# RL6845_IP_SVD register map
Vendor: Realtek
Registers are 32-bit, read-write, reset 0x0 unless marked. A register's access mark holds for its fields unless they carry their own. Offsets are from the block's base; [hi:lo] are bit positions; {n}, {i} and the like mark numbered series.

## PAGE0
Base 0x40000000
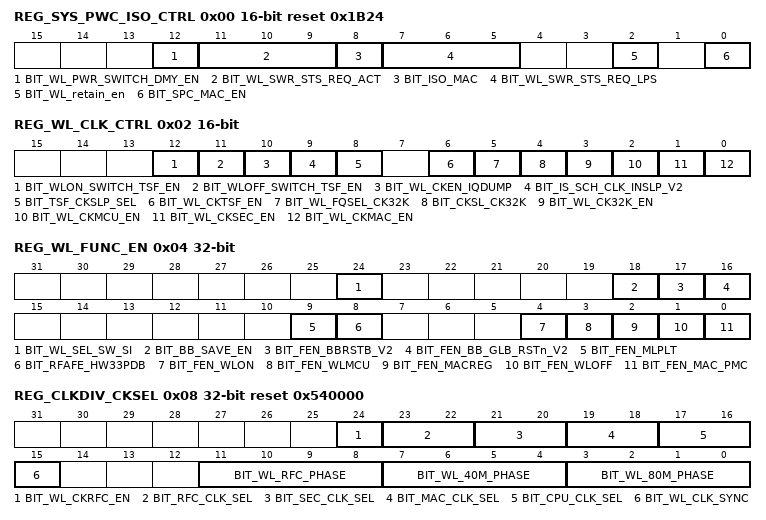
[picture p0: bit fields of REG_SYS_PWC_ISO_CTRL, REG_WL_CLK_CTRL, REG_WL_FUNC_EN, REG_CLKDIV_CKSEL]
0x00 REG_SYS_PWC_ISO_CTRL 16-bit reset 0x1B24
  [12] BIT_WL_PWR_SWITCH_DMY_EN — 1:enable wl_dummy_en when wlan is switching power mode 0:disable wl_dummy_en when wlan is switching power mode
  [11:9] BIT_WL_SWR_STS_REQ_ACT — 000: RSVD 001: state1 0.7/PC/PFM 010: state2 0.8/PC/PFM 011: state3 0.9/PC/PFM 100: state4 0.9/SLP/PFM 101: state5 0.9/SLP/PWM 110: state6 0.9/NORM/PWM 111: state7 1.0/NORM/PWM
  [8] BIT_ISO_MAC — Isolation control for MAC, 1: isolation; 0: attach
  [7:5] BIT_WL_SWR_STS_REQ_LPS — 000: RSVD 001: state1 0.7/PC/PFM 010: state2 0.8/PC/PFM 011: state3 0.9/PC/PFM 100: state4 0.9/SLP/PFM 101: state5 0.9/SLP/PWM 110: state6 0.9/NORM/PWM 111: state7 1.0/NORM/PWM
  [2] BIT_WL_retain_en — 1 to 0:gen req to restore register in power on flow 1:gen req to backup register in power on flow
  [0] BIT_SPC_MAC_EN — 1: Enable WLOFF power cut
0x02 REG_WL_CLK_CTRL 16-bit access per field
  [12] BIT_WLON_SWITCH_TSF_EN rw — enable wlpmc switch TSF clock to MAC clock
  [11] BIT_WLOFF_SWITCH_TSF_EN rw — enable wlpmc switch TSF clock to 32K clock
  [10] BIT_WL_CKEN_IQDUMP rw — 0: disable clock for iqdump (LA MODE) 1: enable clock for iqdump (LA MODE) same clock source as security clock
  [9] BIT_IS_SCH_CLK_INSLP_V2 ro — WL TSF clock status: 0: MAC clock 1: 32K clock
  [8] BIT_TSF_CKSLP_SEL rw — 1: TSF clock switch to 32.768KHz; 0: TSF clock switch to MAC clock
  [6] BIT_WL_CKTSF_EN rw — 1: enable tsf clock; 0: gated
  [5] BIT_WL_FQSEL_CK32K rw — 1:32K frequency select 32.768KHz 0:32K frequency select 32KHz
  [4] BIT_CKSL_CK32K rw — 1:select MAC internal 32K clk, 0:select MAC external 32K clk
  [3] BIT_WL_CK32K_EN rw — 1: enable 32k clock; 0: gated
  [2] BIT_WL_CKMCU_EN rw — 1: enable MCU engine clock; 0: gated
  [1] BIT_WL_CKSEC_EN rw — 1: enable MAC security engine clock; 0: gated
  [0] BIT_WL_CKMAC_EN rw — 1: enable MAC clock; 0: gated
0x04 REG_WL_FUNC_EN access per field
  [24] BIT_WL_SEL_SW_SI rw — indicate SW use indirect path to access WLRFC register
  [18] BIT_BB_SAVE_EN rw — 1 to 0:gen req to restore register in power on flow 1:gen req to backup register in power on flow
  [17] BIT_FEN_BBRSTB_V2 rw — When this bit is set to "0", CCK and OFDM are disabled, and clock are gated. Otherwise, CCK and OFDM are enabled.
  [16] BIT_FEN_BB_GLB_RSTn_V2 rw — When this bit is set to "0", whole BB is reset. When this bit is set, BB is enabled.
  [9] BIT_FEN_MLPLT rw
  [8] BIT_RFAFE_HW33PDB rw
  [4] BIT_FEN_WLON rw — 1: enable WL partial ON; 0: reset
  [3] BIT_FEN_WLMCU rw — 1: enable WLMCU; 0: reset
  [2] BIT_FEN_MACREG rw — 1: enable MAC REG; 0: reset
  [1] BIT_FEN_WLOFF rw — 1: enable WLOFF; 0: reset
  [0] BIT_FEN_MAC_PMC rw — 1: enable MAC PMC; 0: reset
0x08 REG_CLKDIV_CKSEL reset 0x540000
  [24] BIT_WL_CKRFC_EN — 1: enable WLRFC clock; 0: gated
  [23:22] BIT_RFC_CLK_SEL — 11/10:40M 01:80M 00:160M
  [21:20] BIT_SEC_CLK_SEL — 11/10:40M 01:80M 00:160M
  [19:18] BIT_MAC_CLK_SEL — 11/10:20M 01:40M 00:80M
  [17:16] BIT_CPU_CLK_SEL
  [15] BIT_WL_CLK_SYNC — 1: sync 40M/80M clock phase with PLL
  [11:8] BIT_WL_RFC_PHASE — 80M WLRFC clock phase control
  [7:4] BIT_WL_40M_PHASE — 40M MAC clock phase control
  [3:0] BIT_WL_80M_PHASE — 80M security clock phase control
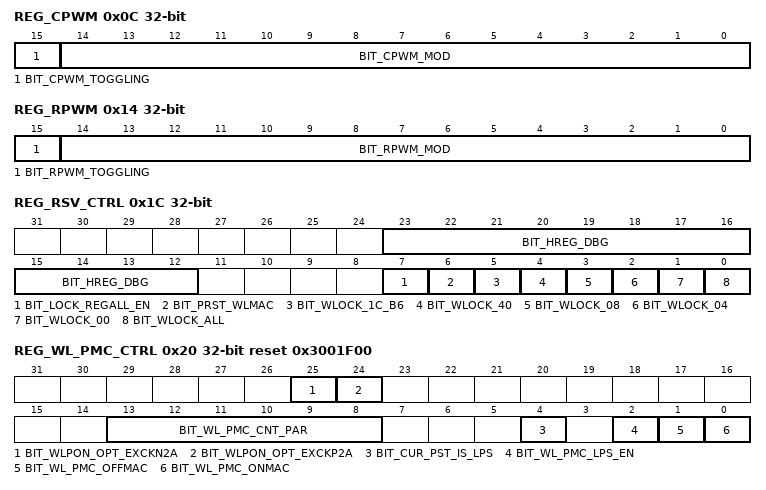
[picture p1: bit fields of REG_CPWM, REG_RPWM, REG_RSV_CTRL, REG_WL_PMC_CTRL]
0x0C REG_CPWM
  [15] BIT_CPWM_TOGGLING — Toggling bit : one bit sequence number bit. When this bit is toggled, interrupt is send to HISR.CPWMINT.
  [14:0] BIT_CPWM_MOD — The current power mode index.
0x14 REG_RPWM — register for hrpwm
  [15] BIT_RPWM_TOGGLING — Toggling bit : one bit sequence number bit. When this bit is toggled, interrupt is send to FISR.RPWMINT.
  [14:0] BIT_RPWM_MOD — The current power mode index.
0x1C REG_RSV_CTRL access per field
  [23:12] BIT_HREG_DBG ro — HREG Access Debug information
  [7] BIT_LOCK_REGALL_EN rw — 1:Enable 'Locked All' setting by Hardware, 0: Hardware Enable 'Locked All' denied.
  [6] BIT_PRST_WLMAC rw
  [5] BIT_WLOCK_1C_B6 rw — 1:Register Write Locked, 0: Register Accessible by SW/FW (offset:0x001C[6])
  [4] BIT_WLOCK_40 rw — 1:Register Write Locked, 0: Register Accessible by SW/FW (offset:0x0040h~0x0043h)
  [3] BIT_WLOCK_08 rw — 1:Register Write Locked, 0: Register Accessible by SW/FW (offset:0x0008h~0x000Bh)
  [2] BIT_WLOCK_04 rw — 1:Register Write Locked, 0: Register Accessible by SW/FW (offset:0x0004h~0x0007h)
  [1] BIT_WLOCK_00 rw — 1:Register Write Locked, 0: Register Accessible by SW/FW (offset:0x0000h~0x0003h)
  [0] BIT_WLOCK_ALL rw — 1:Register Write Locked, 0: Register Accessible by SW/FW (offset:0x0000h~0x00FFh)
0x20 REG_WL_PMC_CTRL access per field reset 0x3001F00
  [25] BIT_WLPON_OPT_EXCKN2A rw
  [24] BIT_WLPON_OPT_EXCKP2A rw — PON option to enable AFE clock
  [13:8] BIT_WL_PMC_CNT_PAR rw — WL PMC FSM counting unit.
  [4] BIT_CUR_PST_IS_LPS ro — indicate current WL power status is LPS mode
  [2] BIT_WL_PMC_LPS_EN rw — Inform WLAN PMC FSM to enter LPS mode. (auto clear when ready)
  [1] BIT_WL_PMC_OFFMAC rw — Inform WLAN PMC FSM to power OFF mode, include clock, isolation, power control for MAC only (clear when Power Ready)
  [0] BIT_WL_PMC_ONMAC rw — Inform WLAN PMC FSM to power On mode, include clock, isolation, power control for MAC only (clear when Power Ready)
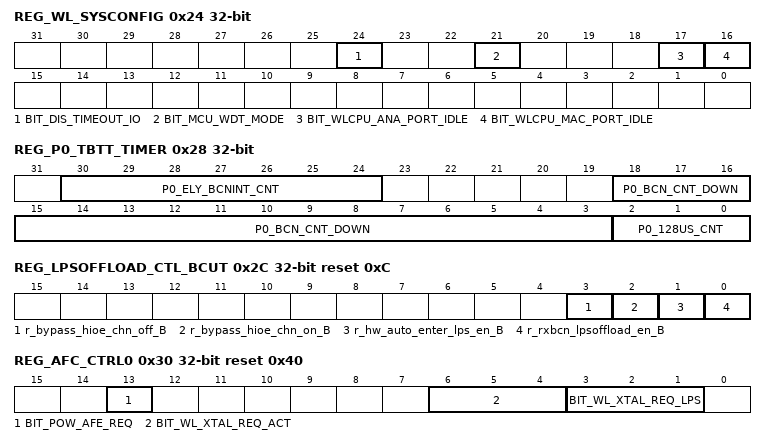
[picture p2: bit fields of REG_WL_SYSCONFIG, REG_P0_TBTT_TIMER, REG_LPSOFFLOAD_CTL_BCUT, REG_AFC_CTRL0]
0x24 REG_WL_SYSCONFIG access per field
  [24] BIT_DIS_TIMEOUT_IO rw — Disabled timeout of IO wrapper
  [21] BIT_MCU_WDT_MODE rw
  [17] BIT_WLCPU_ANA_PORT_IDLE ro
  [16] BIT_WLCPU_MAC_PORT_IDLE ro
0x28 REG_P0_TBTT_TIMER ro
  [30:24] P0_ELY_BCNINT_CNT — Unit: bcn_space the total time to next specified TBTT is (new_ely_agg_cnt - 1) * r_bcn_space(0x554) + (beacon_cnt_down - 1)* 1ms + (cnt_128us + 1)* 128us
  [18:3] P0_BCN_CNT_DOWN — Unit: 1ms beacon_cnt_down - 1
  [2:0] P0_128US_CNT — Unit: 128us
0x2C REG_LPSOFFLOAD_CTL_BCUT reset 0xC
  [3] r_bypass_hioe_chn_off_B — when set 1, bypass request to CHOFF of hioe
  [2] r_bypass_hioe_chn_on_B — when set 1, bypass request to CHON of hioe
  [1] r_hw_auto_enter_lps_en_B — when set 1, enable hw auto enter lps when triggered by lpsoffload
  [0] r_rxbcn_lpsoffload_en_B — when set 1, enable lpsoffload function
0x30 REG_AFC_CTRL0 reset 0x40
  [13] BIT_POW_AFE_REQ — AFE power on request to afe_ctrl 1:request to turn on AFE pwr 0:turn off AFE pwr
  [6:4] BIT_WL_XTAL_REQ_ACT — 000: xtal off 001: xtal lps mode gating 40M 010: xtal lps mode enable 40M 011: xtal normal mode 100:xtal hp mode
  [3:1] BIT_WL_XTAL_REQ_LPS — 000: xtal off 001: xtal lps mode gating 40M 010: xtal lps mode enable 40M 011: xtal normal mode 100:xtal hp mode
0x40 REG_FSIMR_V1
  [0] BIT_FS_BTON_STS_UPDATE_INT_EN — BTON status update interrupt When 0x78[31] toggled, this interrupt is issue to indicate the status updated.
0x44 REG_FSISR_V1 ro
  [0] BIT_FS_BTON_STS_UPDATE_INT — BTON status update interrupt When 0x78[31] toggled, this interrupt is issue to indicate the status updated.
{0x50+4i} REG_FW_DBG{i} (i=0..7)
  [31:0] BIT_FW_DBG{i} — fw debug{i}
0x70 REG_WL_PIN_FUNC_CTRL0
  [31:24] BIT_WL_DBG_SEL — WL debug select
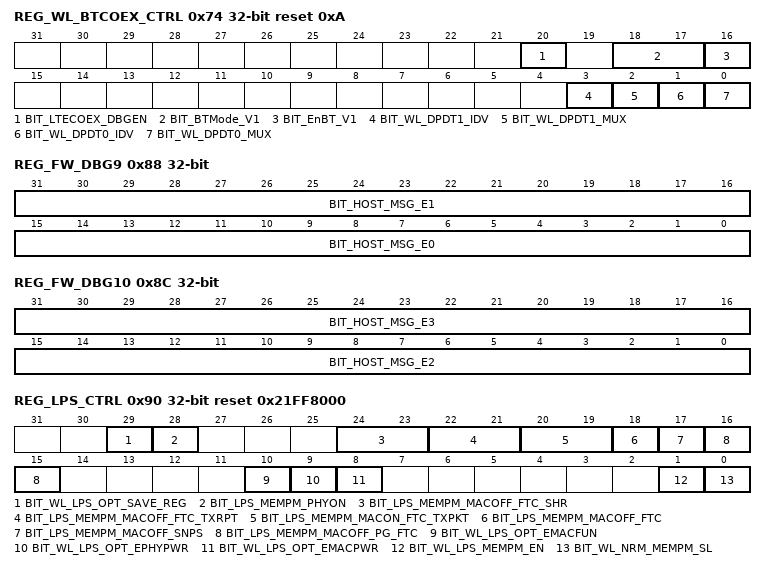
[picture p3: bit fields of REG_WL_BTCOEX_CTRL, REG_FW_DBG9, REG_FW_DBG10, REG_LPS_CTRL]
0x74 REG_WL_BTCOEX_CTRL reset 0xA
  [20] BIT_LTECOEX_DBGEN
  [18:17] BIT_BTMode_V1 — Bluetooth Mode
  [16] BIT_EnBT_V1 — Enable PTA ( from BT side)
  [3] BIT_WL_DPDT1_IDV
  [2] BIT_WL_DPDT1_MUX
  [1] BIT_WL_DPDT0_IDV
  [0] BIT_WL_DPDT0_MUX
0x78 REG_SCOREBOARD_RD_BT2WL ro
  [31:24] BIT_RD_BT2WL_INFO — Read Data : WL TO BT INFO, WLON Status Report
0x7C REG_DBG_PORT_REG ro
  [31:0] BIT_DEBUG_ST — Debug signals, sel by 70[31:24]
0x80 REG_WL_MCUFW_CTRL
  [15] BIT_FW_INIT_RDY — CPU fw initialize ready, set by CPU(txrpt info update,used in ptcl)
0x84 REG_FW_DBG8
  [31:0] BIT_BLK_TST — fw debug8
0x88 REG_FW_DBG9
  [31:16] BIT_HOST_MSG_E1 — User Defined Message
  [15:0] BIT_HOST_MSG_E0 — User Defined Message
0x8C REG_FW_DBG10
  [31:16] BIT_HOST_MSG_E3 — User Defined Message
  [15:0] BIT_HOST_MSG_E2 — User Defined Message
0x90 REG_LPS_CTRL access per field reset 0x21FF8000
  [29] BIT_WL_LPS_OPT_SAVE_REG rw — LPS option to save retention FF 1: enable request to save retention FF 0: disable request to save retention FF
  [28] BIT_LPS_MEMPM_PHYON rw
  [24:23] BIT_LPS_MEMPM_MACOFF_FTC_SHR rw — MAC OFF FTC memory power mode when enable LPS memory power mode(for rxpktbuf/ txpktbuf low 24k[SHARE with system]) 00 : normal 01 : NAP 10 : RET 11 : SLP
  [22:21] BIT_LPS_MEMPM_MACOFF_FTC_TXRPT rw — MAC OFF FTC memory power mode when enable LPS memory power mode (for txrptbuf) 00 : normal 01 : NAP 10 : RET 11 : SLP
  [20:19] BIT_LPS_MEMPM_MACON_FTC_TXPKT rw — MAC ON FTC memory power mode when enable LPS memory power mode (for txpktbuf high 8k) 00 : normal 01 : NAP 10 : RET 11 : SLP
  [18] BIT_LPS_MEMPM_MACOFF_FTC rw — MAC OFF FTC/SNPS memory power mode when enable LPS memory power mode (for rxfifo/txfifo) 0 : normal 1 : NAP/LS
  [17] BIT_LPS_MEMPM_MACOFF_SNPS rw — MAC OFF SNPS memory power mode when enable LPS memory power mode(txllt/rc4/txoqt/keysrch/rxbacam/dmafifo) 0 : normal 1 : NAP
  [16:15] BIT_LPS_MEMPM_MACOFF_PG_FTC rw — MAC OFF FTC memory power mode when enable LPS memory power mode(for rxcsibuf) 00 : normal 01 : NAP 10 : RET 11 : SLP
  [10] BIT_WL_LPS_OPT_EMACFUN rw — LPS option to reset WL MAC OFF block when enable WL MAC OFF power 1: not reset WL MAC OFF block 0: reset WL MAC OFF block
  [9] BIT_WL_LPS_OPT_EPHYPWR rw — LPS option to enable WL BB block power 1: Enable WL BB block power 0: Disable WL BB block power
  [8] BIT_WL_LPS_OPT_EMACPWR rw — LPS option to enable WL MAC OFF block power 1: Enable WL MAC OFF block power 0: Disable WL MAC OFF block power
  [1] BIT_WL_LPS_MEMPM_EN rw — enable LPS memory power mode control
  [0] BIT_WL_NRM_MEMPM_SL rw — MAC memory power mode when BIT_WL_LPS_MEMPM_EN is 0, 0 : Normal 1 : SD
0x94 REG_FW_DBG11
  [31:0] BIT_FW_DBG11 — fw debug11
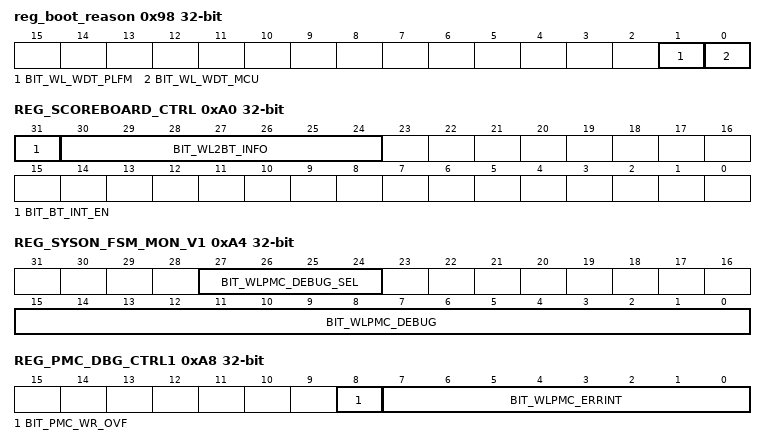
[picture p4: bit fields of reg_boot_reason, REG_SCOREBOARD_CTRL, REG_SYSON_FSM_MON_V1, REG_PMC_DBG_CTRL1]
0x98 reg_boot_reason
  [1] BIT_WL_WDT_PLFM — (not used)
  [0] BIT_WL_WDT_MCU — (not used)
0xA0 REG_SCOREBOARD_CTRL access per field
  [31] BIT_BT_INT_EN wo — For WL, write 1 to issue interrupt 1 : Issue one INT to BT 0 : Don't care
  [30:24] BIT_WL2BT_INFO rw — WLON Status Report TO BTON
0xA4 REG_SYSON_FSM_MON_V1 access per field
  [27:24] BIT_WLPMC_DEBUG_SEL rw — debug select signal for WL PMC
  [15:0] BIT_WLPMC_DEBUG ro — debug signal of WL PMC
0xA8 REG_PMC_DBG_CTRL1 ro
  [8] BIT_PMC_WR_OVF — PMC Write Access Timer Overflow(no use)
  [7:0] BIT_WLPMC_ERRINT — WLPMC Error interrupt(tie 0)
0xAC REG_PMC_DBG_CTRL2_V1
  [1:0] BIT_SYSON_REG_ARB — HW PMC Access Register Time Out Control(no use)
0xE8 REG_SDM_IDR_CTRL0
  [5:0] BIT_SDM_ADDR — SDM register offset
0xEC REG_WL_CK32KGEN_RWD ro
  [31:0] BIT_CK32GEN_RD
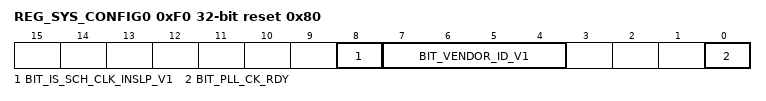
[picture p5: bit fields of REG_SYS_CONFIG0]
0xF0 REG_SYS_CONFIG0 ro reset 0x80
  [8] BIT_IS_SCH_CLK_INSLP_V1 — WL TSF clock status: 0: MAC clock 1: 32K clock
  [7:4] BIT_VENDOR_ID_V1 — Vendor ID [7:6] : Download FW version ; 00: TSMC , 01: SMIC, 10: UMC [5] ; 0 : Download FW , init BB and RF registers 1 : Do not download FW and do not init BB and RF registers [4] ; 0 : BT do not exist in IC 1 : BT exist in IC
  [0] BIT_PLL_CK_RDY — indicate AFE PLL clock is ready
